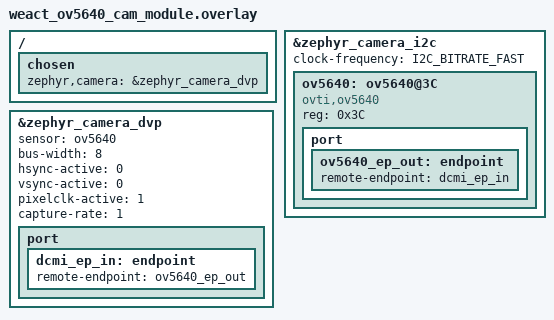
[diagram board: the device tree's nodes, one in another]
/*
 * Copyright (c) Copyright (c) 2024 Charles Dias
 *
 * SPDX-License-Identifier: Apache-2.0
 */

/ {
	chosen {
		zephyr,camera = &zephyr_camera_dvp;
	};
};

&zephyr_camera_i2c {
	status = "okay";
	clock-frequency = <I2C_BITRATE_FAST>;

	ov5640: ov5640@3C {
		compatible = "ovti,ov5640";
		reg = <0x3C>;
		status = "okay";

		port {
			ov5640_ep_out: endpoint {
				remote-endpoint = <&dcmi_ep_in>;
			};
		};
	};
};

&zephyr_camera_dvp {
	status = "okay";
	sensor = <&ov5640>;
	bus-width = <8>;
	hsync-active = <0>;
	vsync-active = <0>;
	pixelclk-active = <1>;
	capture-rate = <1>;

	port {
		dcmi_ep_in: endpoint {
			remote-endpoint = <&ov5640_ep_out>;
		};
	};
};
